VERSION ""

NS_ :

BS_:

BU_:

BO_ 1 Rover_Heartbeat: 1 Vector__XXX
	SG_ Rover_Status : 0|4@1+ (1,0) [0|5] "" Vector__XXX

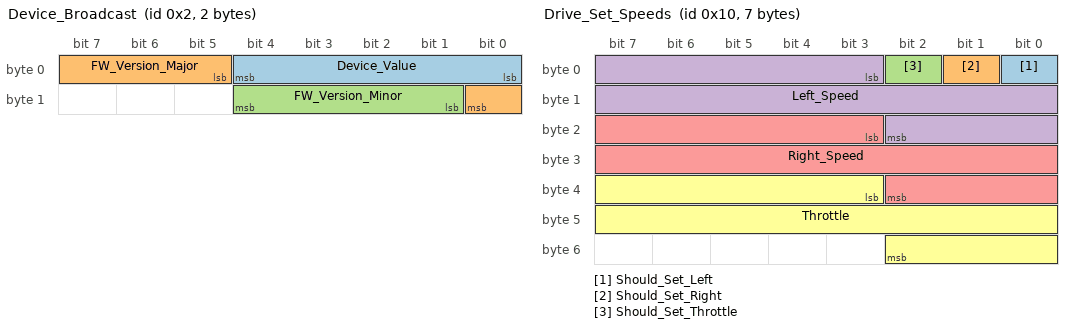
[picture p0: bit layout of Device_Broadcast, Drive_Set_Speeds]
BO_ 2 Device_Broadcast: 2 Vector__XXX
	SG_ Device_Value : 0|5@1+ (1,0) [0|15] "" Vector__XXX
	SG_ FW_Version_Major : 5|4@1+ (1,0) [1|15] "" Vector__XXX
	SG_ FW_Version_Minor : 9|4@1+ (1,0) [0|15] "" Vector__XXX

BO_ 16 Drive_Set_Speeds: 7 Vector__XXX
	SG_ Should_Set_Left : 0|1@1+ (1,0) [0|1] "" Vector__XXX
	SG_ Should_Set_Right : 1|1@1+ (1,0) [0|1] "" Vector__XXX
	SG_ Should_Set_Throttle : 2|1@1+ (1,0) [0|1] "" Vector__XXX
	SG_ Left_Speed : 3|16@1- (0.000062,0) [-1|1] "" Vector__XXX
	SG_ Right_Speed : 19|16@1- (0.000062,0) [-1|1] "" Vector__XXX
	SG_ Throttle : 35|16@1+ (0.000016,0) [0|1] "" Vector__XXX

BO_ 17 Drive_Set_LED: 1 Vector__XXX
	SG_ Color : 0|4@1+ (1,0) [0|8] "" Vector__XXX
	SG_ Blink : 4|1@1+ (1,0) [0|1] "" Vector__XXX

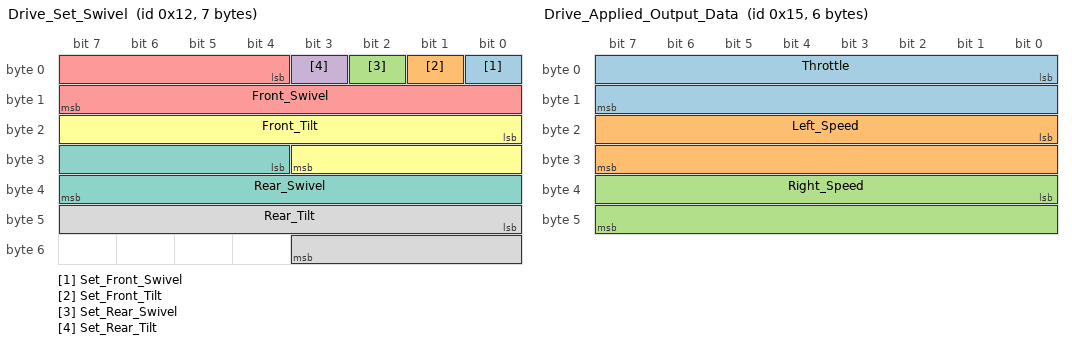
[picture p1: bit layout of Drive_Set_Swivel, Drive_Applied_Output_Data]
BO_ 18 Drive_Set_Swivel: 7 Vector__XXX
	SG_ Set_Front_Swivel : 0|1@1+ (1,0) [0|1] "" Vector__XXX
	SG_ Set_Front_Tilt : 1|1@1+ (1,0) [0|1] "" Vector__XXX
	SG_ Set_Rear_Swivel : 2|1@1+ (1,0) [0|1] "" Vector__XXX
	SG_ Set_Rear_Tilt : 3|1@1+ (1,0) [0|1] "" Vector__XXX
	SG_ Front_Swivel : 4|12@1- (0.044,0) [-90|90] "°" Vector__XXX
	SG_ Front_Tilt : 16|12@1- (0.044,0) [-90|90] "°" Vector__XXX
	SG_ Rear_Swivel : 28|12@1- (0.044,0) [-90|90] "°" Vector__XXX
	SG_ Rear_Tilt : 40|12@1- (0.044,0) [-90|90] "°" Vector__XXX

BO_ 23 Drive_LED_Data: 1 Vector__XXX
	SG_ Color : 0|4@1+ (1,0) [0|8] "" Vector__XXX
	SG_ Blink : 4|1@1+ (1,0) [0|1] "" Vector__XXX

BO_ 21 Drive_Applied_Output_Data: 6 Vector__XXX
	SG_ Throttle : 0|16@1+ (0.000016,0) [0|1] "" Vector__XXX
	SG_ Left_Speed : 16|16@1- (0.000062,0) [-1|1] "" Vector__XXX
	SG_ Right_Speed : 32|16@1- (0.000062,0) [-1|1] "" Vector__XXX

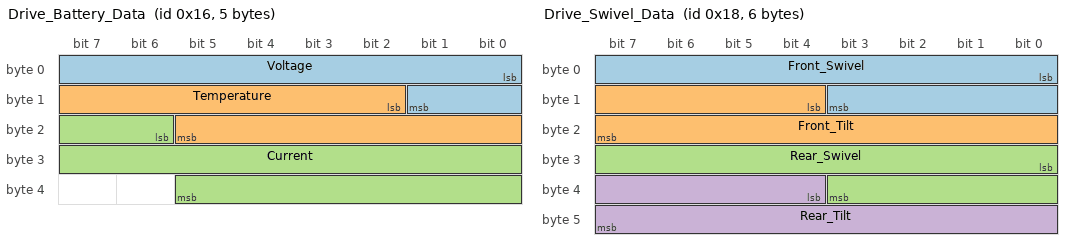
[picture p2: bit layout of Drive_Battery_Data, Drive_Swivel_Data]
BO_ 22 Drive_Battery_Data: 5 Vector__XXX
	SG_ Voltage : 0|10@1+ (0.03548387097,0) [0|36.3] "V" Vector__XXX
	SG_ Temperature : 10|12@1- (0.09,50) [-40|150] "C" Vector__XXX
	SG_ Current : 22|16@1+ (0.1,0) [0|30] "A" Vector__XXX

BO_ 24 Drive_Swivel_Data: 6 Vector__XXX
	SG_ Front_Swivel : 0|12@1- (0.044,0) [-90|90] "°" Vector__XXX
	SG_ Front_Tilt : 12|12@1- (0.044,0) [-90|90] "°" Vector__XXX
	SG_ Rear_Swivel : 24|12@1- (0.044,0) [-90|90] "°" Vector__XXX
	SG_ Rear_Tilt : 36|12@1- (0.044,0) [-90|90] "°" Vector__XXX

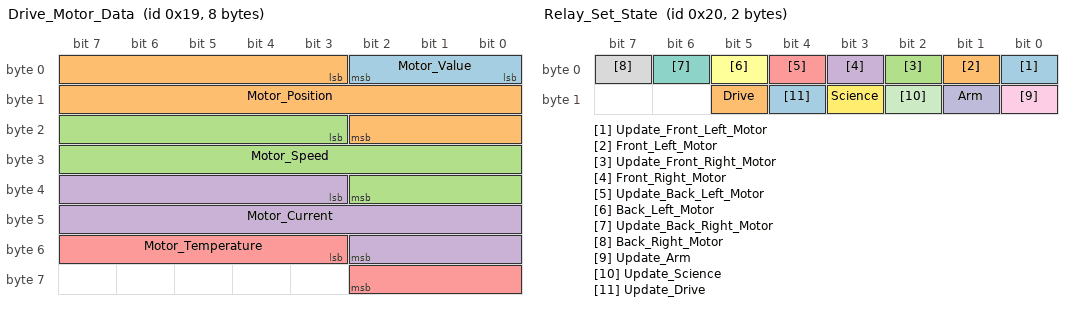
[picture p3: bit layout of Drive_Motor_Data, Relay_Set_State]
BO_ 25 Drive_Motor_Data: 8 Vector__XXX
	SG_ Motor_Value : 0|3@1+ (1,0) [0|6] "" Vector__XXX
	SG_ Motor_Position : 3|16@1- (0.1,0) [-3200|3200] "°" Vector__XXX
	SG_ Motor_Speed : 19|16@1- (10,0) [-320000|320000] "RPM" Vector__XXX
	SG_ Motor_Current : 35|16@1- (0.01,0) [-60|60] "A" Vector__XXX
	SG_ Motor_Temperature : 51|8@1- (1,0) [-20|127] "°C" Vector__XXX

BO_ 32 Relay_Set_State: 2 Vector__XXX
	SG_ Update_Front_Left_Motor : 0|1@1+ (1,0) [0|1] "" Vector__XXX
	SG_ Front_Left_Motor : 1|1@1+ (1,0) [0|1] "" Vector__XXX
	SG_ Update_Front_Right_Motor : 2|1@1+ (1,0) [0|1] "" Vector__XXX
	SG_ Front_Right_Motor : 3|1@1+ (1,0) [0|1] "" Vector__XXX
	SG_ Update_Back_Left_Motor : 4|1@1+ (1,0) [0|1] "" Vector__XXX
	SG_ Back_Left_Motor : 5|1@1+ (1,0) [0|1] "" Vector__XXX
	SG_ Update_Back_Right_Motor : 6|1@1+ (1,0) [0|1] "" Vector__XXX
	SG_ Back_Right_Motor : 7|1@1+ (1,0) [0|1] "" Vector__XXX
	SG_ Update_Arm : 8|1@1+ (1,0) [0|1] "" Vector__XXX
	SG_ Arm : 9|1@1+ (1,0) [0|1] "" Vector__XXX
	SG_ Update_Science : 10|1@1+ (1,0) [0|1] "" Vector__XXX
	SG_ Science : 11|1@1+ (1,0) [0|1] "" Vector__XXX
	SG_ Update_Drive : 12|1@1+ (1,0) [0|1] "" Vector__XXX
	SG_ Drive : 13|1@1+ (1,0) [0|1] "" Vector__XXX

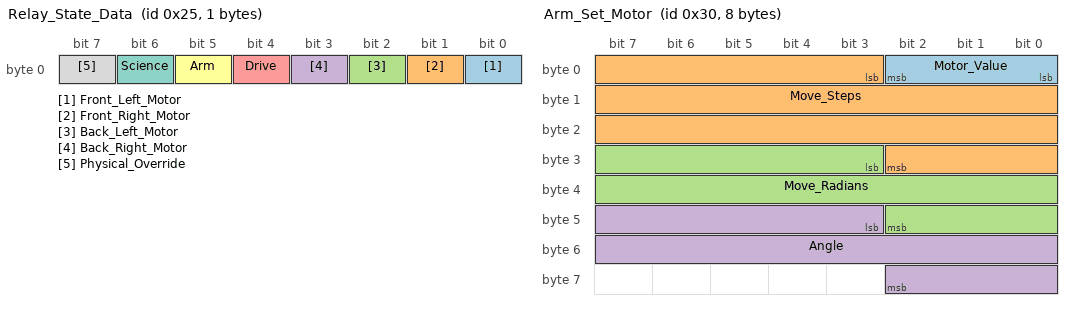
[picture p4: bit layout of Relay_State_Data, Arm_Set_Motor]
BO_ 37 Relay_State_Data: 1 Vector__XXX
	SG_ Front_Left_Motor : 0|1@1+ (1,0) [0|1] "" Vector__XXX
	SG_ Front_Right_Motor : 1|1@1+ (1,0) [0|1] "" Vector__XXX
	SG_ Back_Left_Motor : 2|1@1+ (1,0) [0|1] "" Vector__XXX
	SG_ Back_Right_Motor : 3|1@1+ (1,0) [0|1] "" Vector__XXX
	SG_ Drive : 4|1@1+ (1,0) [0|1] "" Vector__XXX
	SG_ Arm : 5|1@1+ (1,0) [0|1] "" Vector__XXX
	SG_ Science : 6|1@1+ (1,0) [0|1] "" Vector__XXX
	SG_ Physical_Override : 7|1@1+ (1,0) [0|1] "" Vector__XXX

BO_ 48 Arm_Set_Motor: 8 Vector__XXX
	SG_ Motor_Value : 0|3@1+ (1,0) [0|7] "" Vector__XXX
	SG_ Move_Steps : 3|24@1- (1,0) [-8388608|8388608] "" Vector__XXX
	SG_ Move_Radians : 27|16@1- (0.0000958738,0) [-3.1415|3.1415] "" Vector__XXX
	SG_ Angle : 43|16@1- (0.0000958738,0) [-3.1415|-3.1415] "" Vector__XXX

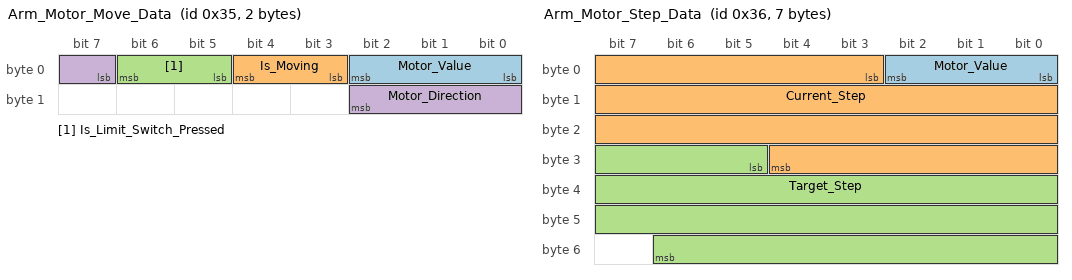
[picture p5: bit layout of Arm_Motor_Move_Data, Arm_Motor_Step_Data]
BO_ 53 Arm_Motor_Move_Data: 2 Vector__XXX
	SG_ Motor_Value : 0|3@1+ (1,0) [0|7] "" Vector__XXX
	SG_ Is_Moving : 3|2@1+ (1,0) [0|2] "" Vector__XXX
	SG_ Is_Limit_Switch_Pressed : 5|2@1+ (1,0) [0|2] "" Vector__XXX
	SG_ Motor_Direction : 7|4@1+ (1,0) [0|9] "" Vector__XXX

BO_ 54 Arm_Motor_Step_Data: 7 Vector__XXX
	SG_ Motor_Value : 0|3@1+ (1,0) [0|7] "" Vector__XXX
	SG_ Current_Step : 3|26@1- (1,0) [-33554432|33554432] "" Vector__XXX
	SG_ Target_Step : 29|26@1- (1,0) [-33554432|3355443208] "" Vector__XXX

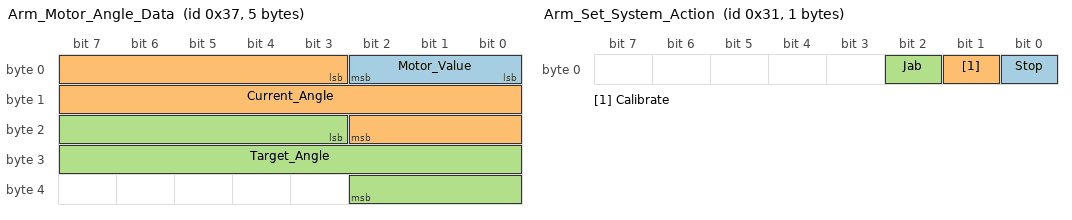
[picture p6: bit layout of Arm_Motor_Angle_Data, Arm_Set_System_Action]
BO_ 55 Arm_Motor_Angle_Data: 5 Vector__XXX
	SG_ Motor_Value : 0|3@1+ (1,0) [0|7] "" Vector__XXX
	SG_ Current_Angle : 3|16@1- (0.00009587379,0) [-3.14159|3.14159] "" Vector__XXX
	SG_ Target_Angle : 19|16@1- (0.00009587379,0) [-3.14159|3.14159] "" Vector__XXX

BO_ 49 Arm_Set_System_Action: 1 Vector__XXX
	SG_ Stop : 0|1@1+ (1,0) [0|1] "" Vector__XXX
	SG_ Calibrate : 1|1@1+ (1,0) [0|1] "" Vector__XXX
	SG_ Jab : 2|1@1+ (1,0) [0|1] "" Vector__XXX

CM_ BO_ 1 "Heartbeat sent from the rover";
CM_ BO_ 2 "Device broadcast message";
CM_ BO_ 16 "Set Drive Speeds";
CM_ BO_ 21 "The applied output of the drive motors";
CM_ BO_ 22 "Information about the battery and current draw";
CM_ BO_ 32 "Command to set the state of the relays";
CM_ BO_ 37 "Data from the relay about the relay state";
CM_ BO_ 17 "Command to set the Drive LED color";
CM_ BO_ 18 "Command to set the swivel angles of drive";
CM_ BO_ 23 "Command to set the LED color on the Drive board";
CM_ BO_ 24 "Data from the drive board about the swivel angles";
CM_ BO_ 25 "Data from an individual drive motor";
CM_ SG_ 48 Motor_Value "Which motor to operate this command on";
CM_ SG_ 48 Move_Steps "How many steps to move the motor";
CM_ SG_ 48 Move_Radians "The amount of radians to move the motor";
CM_ SG_ 48 Angle "The angle in radians to set the motor position to";
CM_ BO_ 48 "Command to operate a specific arm motor";
CM_ BO_ 53 "Movement data from an arm motor";
CM_ BO_ 54 "Step data from an arm motor";
CM_ BO_ 55 "Angle data from an arm motor";
BA_DEF_  "DatabaseVersion" STRING ;
BA_DEF_  "BusType" STRING ;
BA_DEF_  "ProtocolType" STRING ;
BA_DEF_  "DatabaseCompiler" STRING ;
BA_DEF_DEF_  "DatabaseVersion" "";
BA_DEF_DEF_  "BusType" "";
BA_DEF_DEF_  "ProtocolType" "";
BA_DEF_DEF_  "DatabaseCompiler" "";
BA_ "BusType" "CAN";
BA_ "DatabaseCompiler" "CSS ELECTRONICS (WWW.CSSELECTRONICS.COM)";
BA_ "DatabaseVersion" "1.0.0";
